# EDMA3TC register map
Vendor: Texas Instruments
Peripheral module from a debugger description file (folder am437x).
Registers are 32-bit, read-only, no defined reset value unless marked. A register's access mark holds for its fields unless they carry their own. Offsets are as the file gives them; lines under a group give offsets from that group; [hi:lo] are bit positions; {n}, {i} and the like mark numbered series; 'fields as' and 'values as' point back to an identical list; <NAME> marks a mode.

## EDMA3TC
0x00 PID — The peripheral identification register (PID) is a constant register that uniquely identifies the EDMA3TC and specific revision of the EDMA3TC.
  [15:0] PID — Peripheral identifier, value 0 to FFFF FFFFh. [[br]]Reset for PID[31] to PID[16] is 4000h. [[br]]Reset for PID[15] to PID[0] is 7C00h.
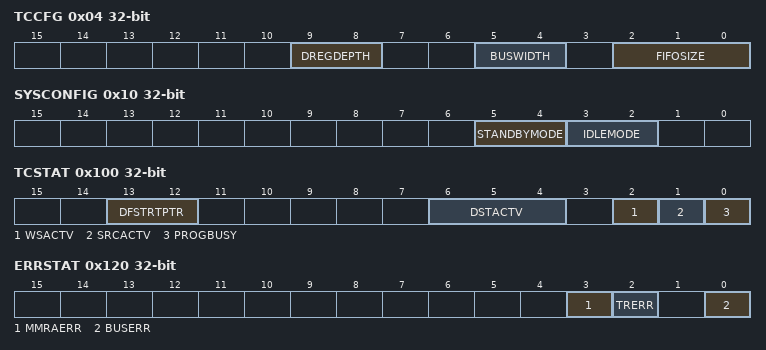
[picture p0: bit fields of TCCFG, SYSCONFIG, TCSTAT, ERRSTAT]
0x04 TCCFG
  [9:8] DREGDEPTH — Destination register FIFO depth parameterization.
    3=en_4_0x3 (Reserved.); 2=en_3_0x2 (4 entry (for TC0, TC1, and TC2)); 1=en_2_0x1 (Reserved.); 0=en_1_0x0 (Reserved.)
  [5:4] BUSWIDTH — Bus width parameterization.
    3=en_4_0x3 (Reserved.); 2=en_3_0x2 (128-bit.); 1=en_2_0x1 (Reserved.); 0=en_1_0x0 (Reserved.)
  [2:0] FIFOSIZE
    7=en_8_0x7 (Reserved.); 6=en_7_0x6 (Reserved.); 5=en_6_0x5 (Reserved.); 4=en_5_0x4 (512 byte FIFO); {v}=en_{v+1}_{0x0+v} (Reserved.) (v=0..3)
0x10 SYSCONFIG access per field
  [5:4] STANDBYMODE rw — Configuration of the local initiator state management mode. [[br]]By definition, initiator may generate read/write transaction as long as it is out of STANDBY state. [[br]]
    3=en_4_0x3 (Reserved.); 2=en_3_0x2 (Smart-standby mode: local initiator standby status depends on local conditions, i.e., the module's functional requirement from the initiator. IP module should not generate (initiator-related) wakeup events.); 1=en_2_0x1 (No-standby mode: local initiator is unconditionally placed out of standby state. Backup mode, for debug only.); 0=en_1_0x0 (Force-standby mode: local initiator is unconditionally placed in standby state. Backup mode, for debug only.)
  [3:2] IDLEMODE rw — Configuration of the local target state management mode. [[br]]By definition, target can handle read/write transaction as long as it is out of IDLE state. [[br]]
    3=en_4_0x3 (Reserved.); 2=en_3_0x2 (Smart-idle mode: local target's idle state eventually follows (acknowledges) the system's idle requests, depending on the IP module's internal requirements. IP module shall not generate (IRQ or DMA-request-related) wakeup events.); 1=en_2_0x1 (No-idle mode: local target never enters idle state. Backup mode, for debug only.); 0=en_1_0x0 (Force-idle mode: local target's idle state follows (acknowledges) the system's idle requests unconditionally, i.e. regardless of the IP module's internal requirements. Backup mode, for debug only.)
0x100 TCSTAT
  [13:12] DFSTRTPTR — Destination FIFO start pointer. [[br]]Represents the offset to the head entry of the destination register FIFO, in units of entries. [[br]]Value 0 to 3h.
  [6:4] DSTACTV — Destination active state. [[br]]Specifies the number of transfer requests (TRs) that are resident in the destination register FIFO at a given instant. [[br]]This bit field can be primarily used for advanced debugging. [[br]]Legal values are constrained by the destination register FIFO depth parameterization (DSTREGDEPTH) parameter. [[br]]
    7=en_8_0x7 (Reserved.); 6=en_7_0x6 (Reserved.); 5=en_6_0x5 (Reserved.); 4=en_5_0x4 (Destination FIFO contains 4 TRs. (Full if DSTREGDEPTH==4). If the destination register FIFO is empty, then any TR written to Prog Set immediately transitions to the destination register FIFO. If the destination register FIFO is not empty and not full, then any TR written to Prog Set immediately transitions to the destination register FIFO set if the source active state (SRCACTV) bit is set to idle. If the destination register FIFO is full, then TRs cannot transition to the destination register FIFO. The destination register FIFO becomes not full when the TR at the head of the destination register FIFO is completed.); 3=en_4_0x3 (Destination FIFO contains 3 TRs.); 2=en_3_0x2 (Destination FIFO contains 2 TRs.); 1=en_2_0x1 (Destination FIFO contains 1 TR.); 0=en_1_0x0 (Destination FIFO is empty.)
  [2] WSACTV — Write status active
    1=en_2_0x1 (Write status is pending. Write status has not been received for all previously issued write commands.); 0=en_1_0x0 (Write status is not pending. Write status has been received for all previously issued write commands.)
  [1] SRCACTV — Source active state
    1=en_2_0x1 (Source controller is busy servicing a transfer request.); 0=en_1_0x0 (Source controller is idle. Source active register set contains a previously processed transfer request.)
  [0] PROGBUSY — Program register set busy
    1=en_2_0x1 (Program set busy); 0=en_1_0x0 (Program set idle and is available for programming by the EDMA3CC.)
0x120 ERRSTAT
  [3] MMRAERR — MMR address error.
    1=en_2_0x1 (User attempted to read or write to an invalid address in configuration memory map.); 0=en_1_0x0 (Condition is not detected.)
  [2] TRERR — Transfer request (TR) error event.
    1=en_2_0x1 (TR detected that violates constant addressing mode transfer (SAM or DAM is set) alignment rules or has ACNT or BCNT == 0.); 0=en_1_0x0 (Condition is not detected.)
  [0] BUSERR — Bus error event.
    1=en_2_0x1 (EDMA3TC has detected an error at source or destination address. Error information can be read from the error details register (ERRDET).); 0=en_1_0x0 (Condition is not detected.)
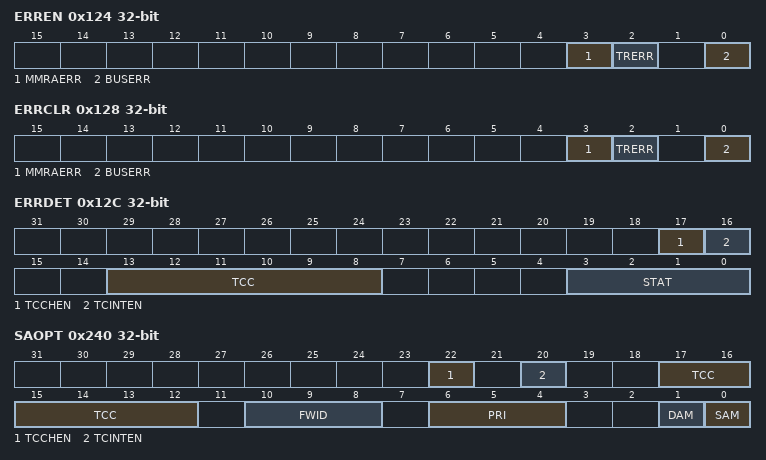
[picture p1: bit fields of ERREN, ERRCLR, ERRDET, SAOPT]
0x124 ERREN access per field — When any of the enable bits are set, a bit set in the corresponding ERRSTAT causes an assertion of the EDMA3TC interrupt.
  [3] MMRAERR rw — Interrupt enable for MMR address error (MMRAERR).
    1=en_2_0x1 (MMRAERR is enabled and contributes to the state of EDMA3TC error interrupt generation); 0=en_1_0x0 (MMRAERR is disabled.)
  [2] TRERR rw — Interrupt enable for transfer request error (TRERR).
    1=en_2_0x1 (TRERR is enabled and contributes to the state of EDMA3TC error interrupt generation.); 0=en_1_0x0 (TRERR is disabled.)
  [0] BUSERR rw — Interrupt enable for bus error (BUSERR).
    1=en_2_0x1 (BUSERR is enabled and contributes to the state of EDMA3TC error interrupt generation.); 0=en_1_0x0 (BUSERR is disabled.)
0x128 ERRCLR access per field
  [3] MMRAERR wo — Interrupt enable clear for the MMRAERR bit in the error status register (ERRSTAT).
    1=en_2_0x1 (Clears the MMRAERR bit in ERRSTAT but does not clear the error details register (ERRDET).); 0=en_1_0x0 (No effect.)
  [2] TRERR wo — Interrupt enable clear for the TRERR bit in the error status register (ERRSTAT).
    1=en_2_0x1 (Clears the TRERR bit in ERRSTAT but does not clear the error details register (ERRDET).); 0=en_1_0x0 (No effect.)
  [0] BUSERR wo — Interrupt clear for the BUSERR bit in the error status register (ERRSTAT).
    1=en_2_0x1 (Clears the BUSERR bit in ERRSTAT and clears the error details register (ERRDET).); 0=en_1_0x0 (No effect.)
0x12C ERRDET
  [17] TCCHEN — Transfer completion chaining enable. [[br]]Contains the TCCHEN value in the channel options parameter (OPT) programmed by the channel controller for the read or write transaction that resulted in an error.
  [16] TCINTEN — Transfer completion interrupt enable. [[br]]Contains the TCINTEN value in the channel options parameter (OPT) programmed by the channel controller for the read or write transaction that resulted in an error.
  [13:8] TCC — Transfer complete code. [[br]]Contains the TCC value in the channel options parameter (OPT) programmed by the channel controller for the read or write transaction that resulted in an error.
  [3:0] STAT — Transaction status. [[br]]Stores the nonzero status/error code that was detected on the read status or write status bus. [[br]]If read status and write status are returned on the same cycle, then the EDMA3TC chooses nonzero version. [[br]]If both are nonzero, then the write status is treated as higher priority. [[br]]
    8=en_3_0x8 (From 8h to Fh, Write error.); 1=en_2_0x1 (From 1h to 7h, Read error.); 0=en_1_0x0 (No error.)
0x130 ERRCMD access per field
  [0] EVAL wo — Error evaluate
    1=en_2_0x1 (EDMA3TC error line is pulsed if any of the error status register (ERRSTAT) bits are set.); 0=en_1_0x0 (No effect)
0x140 RDRATE access per field — The EDMA3 transfer controller issues read commands at a rate controlled by the read rate register (RDRATE). The RDRATE defines the number of idle cycles that the read controller must wait before issuing subsequent commands. This applies both to commands within a transfer request packet (TRP) and for commands that are issued for different transfer requests (TRs). For instance, if RDRATE is set to 4 cycles between reads, there are 3 inactive cycles between reads. RDRATE allows flexibility in transfer controller access requests to an endpoint. For an application, RDRATE can be manipulated to slow down the access rate, so that the endpoint may service requests from other masters during the inactive EDMA3TC cycles. Note: The RDRATE value for a transfer controller is expected to be static, as it is decided based on the application requirement. It is not recommended to change the RDRATE value on the fly.
  [2:0] RDRATE rw — Read rate. [[br]]Controls the number of cycles between read commands. [[br]]This is a global setting that applies to all TRs for this EDMA3TC. [[br]]
    7=en_8_0x7 (Reserved.); 6=en_7_0x6 (Reserved.); 5=en_6_0x5 (Reserved.); 4=en_5_0x4 (32 cycles between reads.); 3=en_4_0x3 (16 cycles between reads.); 2=en_3_0x2 (8 cycles between reads.); 1=en_2_0x1 (4 cycles between reads.); 0=en_1_0x0 (Reads issued as fast as possible.)
0x240 SAOPT — The Source Active Options Register (SAOPT) is an EDMA3TC channel register. This EDMA3TC channel register is part of the Source Active Register Set. It is read-only and provided to facilitate debugging by providing a window into how the transfer controller (TC) was programmed by the channel controller (CC), as well as showing the status of the transfer controller (TC) during a transfer.
  [22] TCCHEN — Transfer complete chaining enable
    1=en_2_0x1 (Transfer complete chaining is enabled.); 0=en_1_0x0 (Transfer complete chaining is disabled.)
  [20] TCINTEN — Transfer complete interrupt enable.
    1=en_2_0x1 (Transfer complete interrupt is enabled.); 0=en_1_0x0 (Transfer complete interrupt is disabled.)
  [17:12] TCC — Transfer complete code. [[br]]This 6 bit code is used to set the relevant bit in CER or IPR of the EDMA3PCC module.
  [10:8] FWID — FIFO width. [[br]]Applies if either SAM or DAM is set to constant addressing mode. [[br]]
    7=en_8_0x7 (Reserved.); 6=en_7_0x6 (Reserved.); 5=en_6_0x5 (FIFO width is 256-bit.); 4=en_5_0x4 (FIFO width is 128-bit.); 3=en_4_0x3 (FIFO width is 64-bit.); 2=en_3_0x2 (FIFO width is 32-bit.); 1=en_2_0x1 (FIFO width is 16-bit.); 0=en_1_0x0 (FIFO width is 8-bit.)
  [6:4] PRI — Transfer priority. [[br]]Reflects the values programmed in the QUEPRI register in the EDMACC. [[br]]
    7=en_3_0x7 (Priority 7 - Lowest priority); 1=en_2_0x1 (From 1h to 6h, Priority 1 to priority 6); 0=en_1_0x0 (Priority 0 - Highest priority)
  [1] DAM — Destination address mode within an array
    1=en_2_0x1 (Constant addressing (CONST) mode. Destination addressing within an array wraps around upon reaching FIFO width.); 0=en_1_0x0 (Increment (INCR) mode. Destination addressing within an array increments.)
  [0] SAM — Source address mode within an array
    1=en_2_0x1 (Constant addressing (CONST) mode. Source addressing within an array wraps around upon reaching FIFO width.); 0=en_1_0x0 (Increment (INCR) mode. Source addressing within an array increments.)
0x244 SASRC — The Source Active Source Address Register (SASRC) is an EDMA3TC channel register. This EDMA3TC channel register is part of the Source Active Register Set. It is read-only and provided to facilitate debugging by providing a window into how the transfer controller (TC) was programmed by the channel controller (CC), as well as showing the status of the transfer controller (TC) during a transfer.
  [31:0] SADDR — Source address for Source Active Register Set. [[br]]EDMA3TC updates value according to source addressing mode (SAM bit in the source active options register, SAOPT). [[br]]This register does not update during a transfer. [[br]]Value 0 to FFFFh.
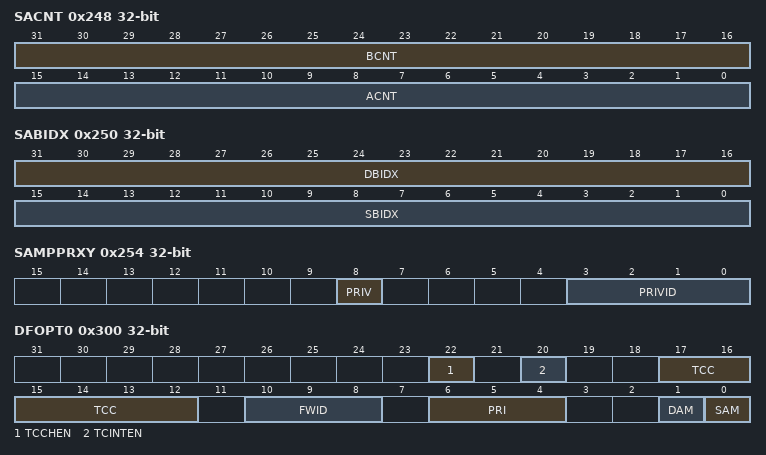
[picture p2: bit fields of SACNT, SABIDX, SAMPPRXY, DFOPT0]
0x248 SACNT — The Source Active Count Register (SACNT) is an EDMA3TC channel register. This EDMA3TC channel register is part of the Source Active Register Set. It is read-only and provided to facilitate debugging by providing a window into how the transfer controller (TC) was programmed by the channel controller (CC), as well as showing the status of the transfer controller (TC) during a transfer.
  [31:16] BCNT — B dimension count remaining for the Source Active Register Set. [[br]]Number of arrays to be transferred, where each array is ACNT in length. [[br]]
  [15:0] ACNT — A dimension count remaining for the Source Active Register Set. [[br]]Number of bytes to be transferred in first dimension. [[br]]
0x24C SADST — The Source Active Destination Address Register (SADST) is an EDMA3TC channel register. This EDMA3TC channel register is part of the Source Active Register Set. It is read-only and provided to facilitate debugging by providing a window into how the transfer controller (TC) was programmed by the channel controller (CC), as well as showing the status of the transfer controller (TC) during a transfer. Note: Destination address is not applicable for Source Active Register Set. Read returns 0.
0x250 SABIDX — The Source Active Source B-Dimension Index Register (SABIDX) is an EDMA3TC channel register. This EDMA3TC channel register is part of the Source Active Register Set. It is read-only and provided to facilitate debugging by providing a window into how the transfer controller (TC) was programmed by the channel controller (CC), as well as showing the status of the transfer controller (TC) during a transfer.
  [31:16] DBIDX — B-Index offset between destination arrays. [[br]]Represents the offset in bytes between the starting address of each destination array (there are BCND arrays of ACNT elements). [[br]]DBIDX is always used regardless of whether DAM is in Increment or FIFO mode. [[br]]
  [15:0] SBIDX — B-Index offset between source arrays. [[br]]Represents the offset in bytes between the starting address of each source array (there are BCNT arrays of ACNT elements). [[br]]SBIDX is always used regardless of whether SAM is in Increment or FIFO mode. [[br]]Value 0 to FFFFh.
0x254 SAMPPRXY — The Source Active Memory Protection Proxy Register (SAMPPRXY) is an EDMA3TC channel register. This EDMA3TC channel register is part of the Source Active Register Set. It is read-only and provided to facilitate debugging by providing a window into how the transfer controller (TC) was programmed by the channel controller (CC), as well as showing the status of the transfer controller (TC) during a transfer.
  [8] PRIV — Privilege level. [[br]]The privilege level used by the host to set up the parameter entry in the channel controller. [[br]]This field is set up when the associated TR is submitted to the EDMA3TC. [[br]]The privilege ID is used while issuing read and write command to the target endpoints so that the target endpoints can perform memory protection checks based on the PRIV of the host that set up the DMA transaction. [[br]]
    1=en_2_0x1 (Supervisor-level privilege.); 0=en_1_0x0 (User-level privilege.)
  [3:0] PRIVID — Privilege ID. [[br]]This contains the privilege ID of the host that set up the parameter entry in the channel controller. [[br]]This field is set up when the associated TR is submitted to the EDMA3TC. [[br]]This PRIVID value is used while issuing read and write commands to the target endpoints so that the target endpoints can perform memory protection checks based on the PRIVID of the host that set up the DMA transaction. [[br]]Value 0 to Fh.
0x258 SACNTRLD — The Source Active Count Reload Register (SACNTRLD) is an EDMA3TC channel register. This EDMA3TC channel register is part of the Source Active Register Set. It is read-only and provided to facilitate debugging by providing a window into how the transfer controller (TC) was programmed by the channel controller (CC), as well as showing the status of the transfer controller (TC) during a transfer.
  [15:0] ACNTRLD — A-count reload value. [[br]]Represents the originally programmed value of ACNT. [[br]]The reload value is used to reinitialize ACNT after each array is serviced (that is, ACNT decrements to 0) by the source offset in bytes between the starting address or each source array (there are BCNT arrays of ACNT bytes). [[br]]Value 0 to FFFFh.
0x25C SASRCBREF — The Source Active Source Address B-Reference Register (SASRCBREF) is an EDMA3TC channel register. This EDMA3TC channel register is part of the Source Active Register Set. It is read-only and provided to facilitate debugging by providing a window into how the transfer controller (TC) was programmed by the channel controller (CC), as well as showing the status of the transfer controller (TC) during a transfer.
  [31:0] SADDRBREF — Source address B-reference. [[br]]Represents the starting address for the array currently being read. [[br]]The next array's starting address is calculated as the reference address plus the source b-idx value. [[br]]Value 0 to FFFF FFFFh.
0x260 SADSTBREF — The Source Active Destination Address B-Reference Register (SADSTBREF) is an EDMA3TC channel register. This EDMA3TC channel register is part of the Source Active Register Set. It is read-only and provided to facilitate debugging by providing a window into how the transfer controller (TC) was programmed by the channel controller (CC), as well as showing the status of the transfer controller (TC) during a transfer. Note: Destination address reference is not applicable for the Source Active Register Set. Read returns 0.
0x280 DFCNTRLD — The Destination FIFO Count Reload Register (DFCNTRLD) is an EDMA3TC channel register. This EDMA3TC channel register is part of the Destination Register FIFO Register Set. It is read-only and provided to facilitate debugging by providing a window into how the transfer controller (TC) was programmed by the channel controller (CC), as well as showing status of the transfer controller (TC) during a transfer. The number of destination FIFO register sets depends on the destination FIFO depth. TC0, TC1, and TC2 each have a destination FIFO depth of 4, so there are four sets of destination FIFO registers for each of these transfer controllers.
  [15:0] ACNTRLD — A-count reload value for the Destination FIFO Register Set. [[br]]Represents the originally programmed value of ACNT. [[br]]The reload value is used to reinitialize ACNT after each array is serviced (that is, ACNT decrements to 0) by the source offset in bytes between the starting address of each source array (there are BCNT arrays of ACNT bytes). [[br]]Value 0 to FFFFh.
0x284 DFSRCBREF — The Destination FIFO Source Address B-Reference Register (DFSRCBREF) is an EDMA3TC channel register. This EDMA3TC channel register is part of the Destination Register FIFO Register Set. It is read-only and provided to facilitate debugging by providing a window into how the transfer controller (TC) was programmed by the channel controller (CC), as well as showing status of the transfer controller (TC) during a transfer. The number of destination FIFO register sets depends on the destination FIFO depth. TC0, TC1, and TC2 each have a destination FIFO depth of 4, so there are four sets of destination FIFO registers for each of these transfer controllers. Note: Source address reference is not applicable for Destination FIFO Register Set. Read returns 0.
0x288 DFDSTBREF — The Destination FIFO Destination Address B-Reference Register (DFDSTBREF) is an EDMA3TC channel register. This EDMA3TC channel register is part of the Destination Register FIFO Register Set. It is read-only and provided to facilitate debugging by providing a window into how the transfer controller (TC) was programmed by the channel controller (CC), as well as showing status of the transfer controller (TC) during a transfer. The number of destination FIFO register sets depends on the destination FIFO depth. TC0, TC1, and TC2 each have a destination FIFO depth of 4, so there are four sets of destination FIFO registers for each of these transfer controllers.
  [31:0] DADDRBREF — Destination address reference for the destination FIFO register set. [[br]]Represents the starting address for the array currently being written. [[br]]The next array's starting address is calculated as the reference address plus the destination B-Index value. [[br]]Value 0 to FFFF FFFFh.
0x300 DFOPT0 — The Destination FIFO Options Register (DFOPT) is an EDMA3TC channel register. This EDMA3TC channel register is part of the Destination Register FIFO Register Set. It is read-only and provided to facilitate debugging by providing a window into how the transfer controller (TC) was programmed by the channel controller (CC), as well as showing status of the transfer controller (TC) during a transfer. The number of destination FIFO register sets depends on the destination FIFO depth. TC0, TC1, and TC2 each have a destination FIFO depth of 4, so there are four sets of destination FIFO registers for each of these transfer controllers.
  [22] TCCHEN — Transfer complete chaining enable
    1=en_2_0x1 (Transfer complete chaining is enabled); 0=en_1_0x0 (Transfer complete chaining is disabled)
  [20] TCINTEN — Transfer complete interrupt enable.
    values as SAOPT.TCINTEN
  [17:12] TCC — Transfer complete code. [[br]]This 6 bit code is used to set the relevant bit in CER or IPR of the EDMA3PCC module.
  [10:8] FWID — FIFO width. [[br]]Applies if either SAM or DAM is set to constant addressing mode. [[br]]
    values as SAOPT.FWID
  [6:4] PRI — Transfer priority
    values as SAOPT.PRI
  [1] DAM — Destination address mode within an array
    values as SAOPT.DAM
  [0] SAM — Source address mode within an array
    values as SAOPT.SAM
0x304 DFSRC0 — The Destination FIFO Source Address Register (DFSRC) is an EDMA3TC channel register. This EDMA3TC channel register is part of the Destination Register FIFO Register Set. It is read-only and provided to facilitate debugging by providing a window into how the transfer controller (TC) was programmed by the channel controller (CC), as well as showing status of the transfer controller (TC) during a transfer. The number of destination FIFO register sets depends on the destination FIFO depth. TC0, TC1, and TC2 each have a destination FIFO depth of 4, so there are four sets of destination FIFO registers for each of these transfer controllers. Note: Source address is not applicable for Destination FIFO Register Set. Read returns 0.
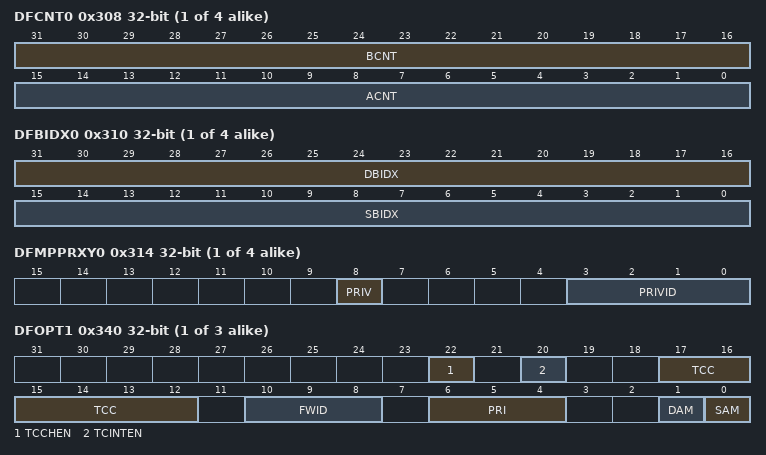
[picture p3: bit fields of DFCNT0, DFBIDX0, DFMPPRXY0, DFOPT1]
{0x308+0x40*i} DFCNT{i} (i=0..3) — The Destination FIFO Count Register (DFCNT) is an EDMA3TC channel register. This EDMA3TC channel register is part of the Destination Register FIFO Register Set. It is read-only and provided to facilitate debugging by providing a window into how the transfer controller (TC) was programmed by the channel controller (CC), as well as showing status of the transfer controller (TC) during a transfer. The number of destination FIFO register sets depends on the destination FIFO depth. TC0, TC1, and TC2 each have a destination FIFO depth of 4, so there are four sets of destination FIFO registers for each of these transfer controllers.
  [31:16] BCNT — B-dimension count remaining for Destination Register Set. [[br]]Represents the amount of data remaining to be written. [[br]]For the final TR in the Destination Register FIFO: TC decrements ACNT and BCNT as necessary after each write dataphase is issued. [[br]]The final value should be 0 when TR is complete. [[br]]For a non-final TR in the Destination Register FIFO: CNT will hold the originally programmed value or the optimized BCNT value after 2D optimization calculation.
  [15:0] ACNT — A-dimension count remaining for Destination Register Set. [[br]]Represents the amount of data remaining to be written. [[br]]For the final TR in the Destination Register FIFO: TC decrements ACNT and BCNT as necessary after each write dataphase is issued. [[br]]The final value should be 0 when TR is complete. [[br]]For a non-final TR in the Destination Register FIFO: CNT will hold the originally programmed value or the optimized BCNT value after 2D optimization calculation. [[br]]Value 0 to FFFFh.
0x30C DFDST0 — The Destination FIFO Destination Address Register (DFDST) is an EDMA3TC channel register. This EDMA3TC channel register is part of the Destination Register FIFO Register Set. It is read-only and provided to facilitate debugging by providing a window into how the transfer controller (TC) was programmed by the channel controller (CC), as well as showing status of the transfer controller (TC) during a transfer. The number of destination FIFO register sets depends on the destination FIFO depth. TC0, TC1, and TC2 each have a destination FIFO depth of 4, so there are four sets of destination FIFO registers for each of these transfer controllers.
  [31:0] DADDR — ARRAY(0x24369c0) Note: If DAM == CONST, the 'active' address will increment internally as if the transfer were an 'Increment' transfer. [[br]]The address issued on the write command interface will correctly issue the same address programmed by the user.
{0x310+0x40*i} DFBIDX{i} (i=0..3) — The Destination FIFO B-Index Register (DFBIDX) is an EDMA3TC channel register. This EDMA3TC channel register is part of the Destination Register FIFO Register Set. It is read-only and provided to facilitate debugging by providing a window into how the transfer controller (TC) was programmed by the channel controller (CC), as well as showing status of the transfer controller (TC) during a transfer. The number of destination FIFO register sets depends on the destination FIFO depth. TC0, TC1, and TC2 each have a destination FIFO depth of 4, so there are four sets of destination FIFO registers for each of these transfer controllers.
  [31:16] DBIDX — B-Index offset between destination arrays for the Destination FIFO Register Set. [[br]]Represents the offset in bytes between the starting address of each destination array (there are BCNT arrays of ACNT elements). [[br]]DBIDX is always used regardless of whether DAM is in Increment or FIFO mode. [[br]]Value 0 to FFFFh.
  [15:0] SBIDX — B-Index offset between source arrays for the Destination FIFO Register Set. [[br]]Represents the offset in bytes between the starting address of each source array (there are BCNT arrays of ACNT elements). [[br]]SBIDX is always used regardless of whether SAM is in Increment or FIFO mode.
{0x314+0x40*i} DFMPPRXY{i} (i=0..3) — The Destination FIFO Memory Protection Proxy Register (DFMPPRXY) is an EDMA3TC channel register. This EDMA3TC channel register is part of the Destination Register FIFO Register Set. It is read-only and provided to facilitate debugging by providing a window into how the transfer controller (TC) was programmed by the channel controller (CC), as well as showing status of the transfer controller (TC) during a transfer. The number of destination FIFO register sets depends on the destination FIFO depth. TC0, TC1, and TC2 each have a destination FIFO depth of 4, so there are four sets of destination FIFO registers for each of these transfer controllers.
  [8] PRIV — Privilege level. [[br]]This contains the Privilege level used by the EDMA3 programmer to set up the parameter entry in the channel controller. [[br]]This field is set up when the associated TR is submitted to the EDMA3TC. [[br]]The privilege ID is used while issuing read and write command to the target endpoints so that the target endpoints can perform memory protection checks based on the PRIV of the host that set up the DMA transaction. [[br]]
    1=en_2_0x1 (Supervisor-level privilege); 0=en_1_0x0 (User-level privilege)
  [3:0] PRIVID — Privilege ID. [[br]]This contains the Privilege ID of the EDMA3 programmer that set up the parameter entry in the channel controller. [[br]]This field is set up when the associated TR is submitted to the EDMA3TC. [[br]]This PRIVID value is used while issuing read and write commands to the target endpoints so that the target endpoints can perform memory protection checks based on the PRIVID of the host that set up the DMA transaction. [[br]]Value 0 to Fh.
{0x300+0x40*i} DFOPT{i} (i=1..3) — The Destination FIFO Options Register (DFOPT) is an EDMA3TC channel register. This EDMA3TC channel register is part of the Destination Register FIFO Register Set. It is read-only and provided to facilitate debugging by providing a window into how the transfer controller (TC) was programmed by the channel controller (CC), as well as showing status of the transfer controller (TC) during a transfer. The number of destination FIFO register sets depends on the destination FIFO depth. TC0, TC1, and TC2 each have a destination FIFO depth of 4, so there are four sets of destination FIFO registers for each of these transfer controllers.
  [22] TCCHEN — Transfer complete chaining enable
    values as DFOPT0.TCCHEN
  [20] TCINTEN — Transfer complete interrupt enable.
    values as SAOPT.TCINTEN
  [17:12] TCC — Transfer complete code. [[br]]This 6 bit code is used to set the relevant bit in CER or IPR of the EDMA3PCC module.
  [10:8] FWID — FIFO width. [[br]]Applies if either SAM or DAM is set to constant addressing mode. [[br]]
    7=en_8_0x7 (Reserved. Always write 0 to this bit; writes of 1 to this bit are not supported and attempts to do so may result in undefined behavior.); 6=en_7_0x6 (Reserved. Always write 0 to this bit; writes of 1 to this bit are not supported and attempts to do so may result in undefined behavior.); 5=en_6_0x5 (FIFO width is 256-bit.); 4=en_5_0x4 (FIFO width is 128-bit.); 3=en_4_0x3 (FIFO width is 64-bit.); 2=en_3_0x2 (FIFO width is 32-bit.); 1=en_2_0x1 (FIFO width is 16-bit.); 0=en_1_0x0 (FIFO width is 8-bit.)
  [6:4] PRI — Transfer priority
    values as SAOPT.PRI
  [1] DAM — Destination address mode within an array
    values as SAOPT.DAM
  [0] SAM — Source address mode within an array
    values as SAOPT.SAM
0x344 DFSRC1 — The Destination FIFO Source Address Register (DFSRC) is an EDMA3TC channel register. This EDMA3TC channel register is part of the Destination Register FIFO Register Set. It is read-only and provided to facilitate debugging by providing a window into how the transfer controller (TC) was programmed by the channel controller (CC), as well as showing status of the transfer controller (TC) during a transfer. The number of destination FIFO register sets depends on the destination FIFO depth. TC0, TC1, and TC2 each have a destination FIFO depth of 4, so there are four sets of destination FIFO registers for each of these transfer controllers. Note: Source address is not applicable for the Destination FIFO Register Set. Read returns 0.
0x34C DFDST1 — The Destination FIFO Destination Address Register (DFDST) is an EDMA3TC channel register. This EDMA3TC channel register is part of the Destination Register FIFO Register Set. It is read-only and provided to facilitate debugging by providing a window into how the transfer controller (TC) was programmed by the channel controller (CC), as well as showing status of the transfer controller (TC) during a transfer. The number of destination FIFO register sets depends on the destination FIFO depth. TC0, TC1, and TC2 each have a destination FIFO depth of 4, so there are four sets of destination FIFO registers for each of these transfer controllers.
  [31:0] DADDR — ARRAY(0x245d830) Note: If DAM == CONST, the 'active' address will increment internally as if the transfer were an 'Increment' transfer. [[br]]The address issued on the write command interface will correctly issue the same address programmed by the user.
0x384 DFSRC2 — The Destination FIFO Source Address Register (DFSRC) is an EDMA3TC channel register. This EDMA3TC channel register is part of the Destination Register FIFO Register Set. It is read-only and provided to facilitate debugging by providing a window into how the transfer controller (TC) was programmed by the channel controller (CC), as well as showing status of the transfer controller (TC) during a transfer. The number of destination FIFO register sets depends on the destination FIFO depth. TC0, TC1, and TC2 each have a destination FIFO depth of 4, so there are four sets of destination FIFO registers for each of these transfer controllers. Note: Source address is not applicable for Destination FIFO Register Set. Read returns 0.
0x38C DFDST2 — The Destination FIFO Destination Address Register (DFDST) is an EDMA3TC channel register. This EDMA3TC channel register is part of the Destination Register FIFO Register Set. It is read-only and provided to facilitate debugging by providing a window into how the transfer controller (TC) was programmed by the channel controller (CC), as well as showing status of the transfer controller (TC) during a transfer. The number of destination FIFO register sets depends on the destination FIFO depth. TC0, TC1, and TC2 each have a destination FIFO depth of 4, so there are four sets of destination FIFO registers for each of these transfer controllers.
  [31:0] DADDR — ARRAY(0x248ac60) Note: If DAM == CONST, the 'active' address will increment internally as if the transfer were an 'Increment' transfer. [[br]]The address issued on the write command interface will correctly issue the same address programmed by the user.
0x3C4 DFSRC3 — The Destination FIFO Source Address Register (DFSRC) is an EDMA3TC channel register. This EDMA3TC channel register is part of the Destination Register FIFO Register Set. It is read-only and provided to facilitate debugging by providing a window into how the transfer controller (TC) was programmed by the channel controller (CC), as well as showing status of the transfer controller (TC) during a transfer. The number of destination FIFO register sets depends on the destination FIFO depth. TC0, TC1, and TC2 each have a destination FIFO depth of 4, so there are four sets of destination FIFO registers for each of these transfer controllers. Note: Source address is not applicable for Destination FIFO Register Set. Read returns 0.
0x3CC DFDST3 — The Destination FIFO Destination Address Register (DFDST) is an EDMA3TC channel register. This EDMA3TC channel register is part of the Destination Register FIFO Register Set. It is read-only and provided to facilitate debugging by providing a window into how the transfer controller (TC) was programmed by the channel controller (CC), as well as showing status of the transfer controller (TC) during a transfer. The number of destination FIFO register sets depends on the destination FIFO depth. TC0, TC1, and TC2 each have a destination FIFO depth of 4, so there are four sets of destination FIFO registers for each of these transfer controllers.
  [31:0] DADDR — ARRAY(0x24b1d10) Note: If DAM == CONST, the 'active' address will increment internally as if the transfer were an 'Increment' transfer. [[br]]The address issued on the write command interface will correctly issue the same address programmed by the user.
